# DEC register map
Vendor: Texas Instruments
Peripheral module from a debugger description file (folder ucd3138128).
Registers are 32-bit, access not given, no defined reset value unless marked. A register's access mark holds for its fields unless they carry their own. Offsets are as the file gives them; lines under a group give offsets from that group; [hi:lo] are bit positions; {n}, {i} and the like mark numbered series; 'fields as' and 'values as' point back to an identical list; <NAME> marks a mode.

## DEC
{0x0+8i} MFBAHR{i} (i=0..17) — Memory Fine Base Address High Register {i}
  [15:0] ADDRESS rw — Address[31:16]
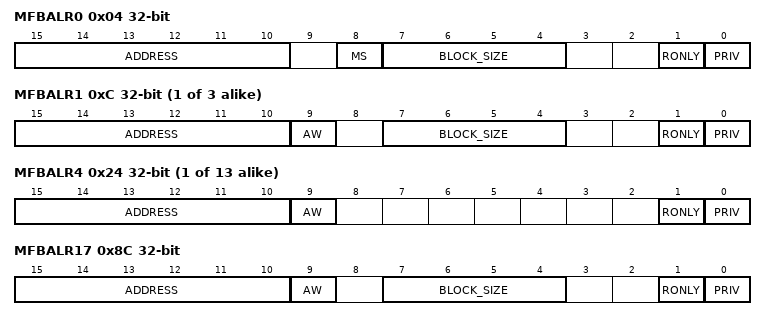
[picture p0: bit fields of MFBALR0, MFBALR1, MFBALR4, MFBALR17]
0x04 MFBALR0 — Memory Fine Base Address Low Register 0
  [15:10] ADDRESS rw — Address[15:10]
  [8] MS rw — Memory map select
  [7:4] BLOCK_SIZE rw
  [1] RONLY rw — Read-only protection
  [0] PRIV rw — Privilege mode protection
{0x4+8i} MFBALR{i} (i=1..3) — Memory Fine Base Address Low Register {i}
  [15:10] ADDRESS rw — Address[15:10]
  [9] AW rw — Auto-wait-on-write
  [7:4] BLOCK_SIZE rw
  [1] RONLY rw — Read-only protection
  [0] PRIV rw — Privilege mode protection
{0x4+8i} MFBALR{i} (i=4..16) — Memory Fine Base Address Low Register {i}
  [15:10] ADDRESS rw — Address[15:10]
  [9] AW rw — Auto-wait-on-write
  [1] RONLY rw — Read-only protection
  [0] PRIV rw — Privilege mode protection
0x8C MFBALR17 — Memory Fine Base Address Low Register 17
  fields as MFBALR1
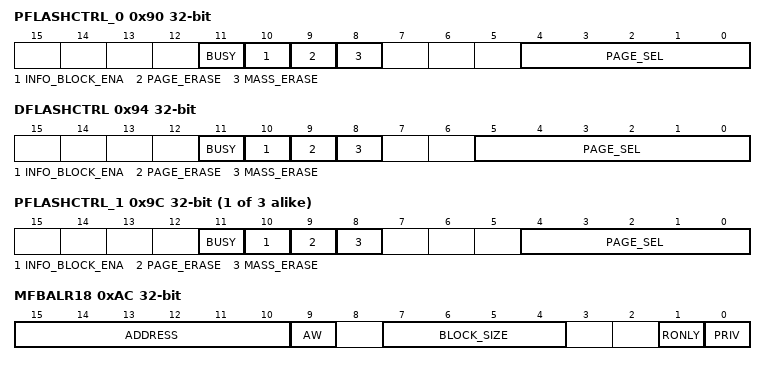
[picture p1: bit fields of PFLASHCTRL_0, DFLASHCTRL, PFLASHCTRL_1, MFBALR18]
0x90 PFLASHCTRL_0 — Program Flash Control Register 0
  [11] BUSY ro — Flash busy
  [10] INFO_BLOCK_ENA rw — Info block enable
  [9] PAGE_ERASE rw — Page erase enable
  [8] MASS_ERASE rw — Mass erase enable
  [4:0] PAGE_SEL rw — Page selection
0x94 DFLASHCTRL — Data Flash Control Register
  [11] BUSY ro — Flash busy
  [10] INFO_BLOCK_ENA rw — Info block enable
  [9] PAGE_ERASE rw — Page erase enable
  [8] MASS_ERASE rw — Mass erase enable
  [5:0] PAGE_SEL rw — Page selection
0x98 FLASHILOCK rw — Program Flash Interlock Register
  [31:0] INTERLOCK_KEY
{0x98+4i} PFLASHCTRL_{i} (i=1..3) — Program Flash Control Register {i}
  fields as PFLASHCTRL_0
0xA8 MFBAHR18 — Memory Fine Base Address High Register 18
  [15:0] ADDRESS rw — Address[31:16]
0xAC MFBALR18 — Memory Fine Base Address Low Register 18
  fields as MFBALR1
0xB0 MFBAHR19 — Memory Fine Base Address High Register 19
  [15:0] ADDRESS rw — Address[31:16]
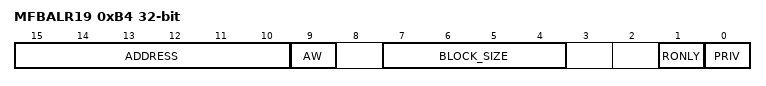
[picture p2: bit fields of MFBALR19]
0xB4 MFBALR19 — Memory Fine Base Address Low Register 19
  fields as MFBALR1
